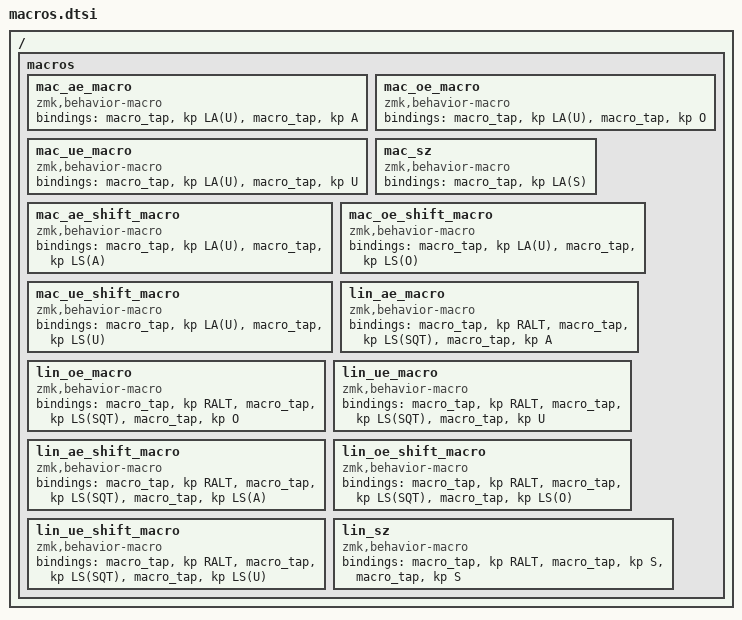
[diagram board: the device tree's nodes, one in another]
/ {
    macros {

        /* macOS lowercase */

        mac_ae_macro: mac_ae_macro {
            compatible = "zmk,behavior-macro";
            #binding-cells = <0>;
            bindings =
                <&macro_tap &kp LA(U)>
                , <&macro_tap &kp A>;
        };

        mac_oe_macro: mac_oe_macro {
            compatible = "zmk,behavior-macro";
            #binding-cells = <0>;
            bindings =
                <&macro_tap &kp LA(U)>
                , <&macro_tap &kp O>;
        };

        mac_ue_macro: mac_ue_macro {
            compatible = "zmk,behavior-macro";
            #binding-cells = <0>;
            bindings =
                <&macro_tap &kp LA(U)>
                , <&macro_tap &kp U>;
        };

        mac_sz: mac_sz {
            compatible = "zmk,behavior-macro";
            #binding-cells = <0>;
            bindings =
                <&macro_tap &kp LA(S)>;
        };


        /* macOS uppercase */

        mac_ae_shift_macro: mac_ae_shift_macro {
            compatible = "zmk,behavior-macro";
            #binding-cells = <0>;
            bindings =
                <&macro_tap &kp LA(U)>
                , <&macro_tap &kp LS(A)>;
        };

        mac_oe_shift_macro: mac_oe_shift_macro {
            compatible = "zmk,behavior-macro";
            #binding-cells = <0>;
            bindings =
                <&macro_tap &kp LA(U)>
                , <&macro_tap &kp LS(O)>;
        };

        mac_ue_shift_macro: mac_ue_shift_macro {
            compatible = "zmk,behavior-macro";
            #binding-cells = <0>;
            bindings =
                <&macro_tap &kp LA(U)>
                , <&macro_tap &kp LS(U)>;
        };


        /* Linux lowercase */

        lin_ae_macro: lin_ae_macro {
            compatible = "zmk,behavior-macro";
            #binding-cells = <0>;
            bindings =
                <&macro_tap &kp RALT>
                , <&macro_tap &kp LS(SQT)>
                , <&macro_tap &kp A>;
        };

        lin_oe_macro: lin_oe_macro {
            compatible = "zmk,behavior-macro";
            #binding-cells = <0>;
            bindings =
                <&macro_tap &kp RALT>
                , <&macro_tap &kp LS(SQT)>
                , <&macro_tap &kp O>;
        };

        lin_ue_macro: lin_ue_macro {
            compatible = "zmk,behavior-macro";
            #binding-cells = <0>;
            bindings =
                <&macro_tap &kp RALT>
                , <&macro_tap &kp LS(SQT)>
                , <&macro_tap &kp U>;
        };


        /* Linux uppercase */

        lin_ae_shift_macro: lin_ae_shift_macro {
            compatible = "zmk,behavior-macro";
            #binding-cells = <0>;
            bindings =
                <&macro_tap &kp RALT>
                , <&macro_tap &kp LS(SQT)>
                , <&macro_tap &kp LS(A)>;
        };

        lin_oe_shift_macro: lin_oe_shift_macro {
            compatible = "zmk,behavior-macro";
            #binding-cells = <0>;
            bindings =
                <&macro_tap &kp RALT>
                , <&macro_tap &kp LS(SQT)>
                , <&macro_tap &kp LS(O)>;
        };

        lin_ue_shift_macro: lin_ue_shift_macro {
            compatible = "zmk,behavior-macro";
            #binding-cells = <0>;
            bindings =
                <&macro_tap &kp RALT>
                , <&macro_tap &kp LS(SQT)>
                , <&macro_tap &kp LS(U)>;
        };

        lin_sz: lin_sz {
            compatible = "zmk,behavior-macro";
            #binding-cells = <0>;
            bindings =
                <&macro_tap &kp RALT>
                , <&macro_tap &kp S>
                , <&macro_tap &kp S>;
        };

    };
};
